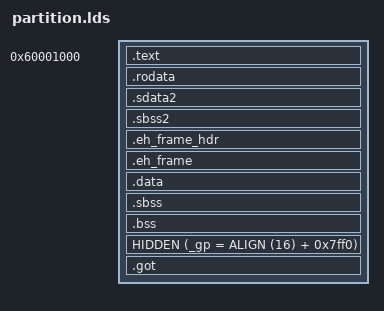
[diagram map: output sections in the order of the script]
/* Script for -z combreloc: combine and sort reloc sections */
/* Copyright (C) 2014-2015 Free Software Foundation, Inc.
   Copying and distribution of this script, with or without modification,
   are permitted in any medium without royalty provided the copyright
   notice and this notice are preserved.  */
OUTPUT_FORMAT("elf32-tradbigmips")
OUTPUT_ARCH(mips)
ENTRY(__pok_partition_start)
SECTIONS
{
	kshd = 0x70000000; /* This should coincide with ja_space_shared_data() in the kernel. */

  . = 0x60001000;

	__partition_begin = . ;
        .text           :
        {
           *(.text .text.*)
           __text_end = .;
        }
        .rodata :
        {
          *(.rodata .rodata.*)
          *(.rodata1)
          . = ALIGN(4);
          __rodata_end = .;
        }

        .sdata2 :
        {
          __sdata2_start = .;
          PROVIDE (_SDA2_BASE_ = 32768);
          *(.sdata2 .sdata2.* .gnu.linkonce.s2.*)
          . = ALIGN(4);
          __sdata2_end = .;
        }
        .sbss2 :
        {
          __sbss2_start = .;
          *(.sbss2 .sbss2.* .gnu.linkonce.sb2.*)
          . = ALIGN(4);
          __sbss2_end = .;
        }
        .eh_frame_hdr : { *(.eh_frame_hdr) *(.eh_frame_entry .eh_frame_entry.*) }
        .eh_frame       : ONLY_IF_RO { KEEP (*(.eh_frame)) *(.eh_frame.*) }
    
        .data :
        {
          __data_start = .;
          *(.data .data.* .gnu.linkonce.d.*)
          *(.data1)
          PROVIDE (_SDA_BASE_ = 32768);
          *(.sdata .sdata.* .gnu.linkonce.s.*)
          . = ALIGN(4);
          __data_end = .;
        }

        .sbss :
        {
          __sbss_start = .;
          *(.dynsbss)
          *(.sbss .sbss.* .gnu.linkonce.sb.*)
          *(.scommon)
          __sbss_end = .;
        }
        .bss  :
        {
          __bss_start = .;
          *(.dynbss)
          *(.bss .bss.* .gnu.linkonce.b.*)
          *(COMMON)
          . = ALIGN(4);
          __bss_end = .;

          _end = .;
        }
        HIDDEN (_gp = ALIGN (16) + 0x7ff0);
        .got            : { *(.got) }
	__partition_end = . ;
}

